# pmac_rx_secure register map
Vendor: Texas Instruments
Registers are 32-bit, read-only, reset 0x0 unless marked. A register's access mark holds for its fields unless they carry their own. Offsets are as the file gives them; [hi:lo] are bit positions; lines under a group give offsets from that group; {n}, {i} and the like mark numbered series; <NAME> marks a mode.

## pmac_rx_secure (part 2 of 3)
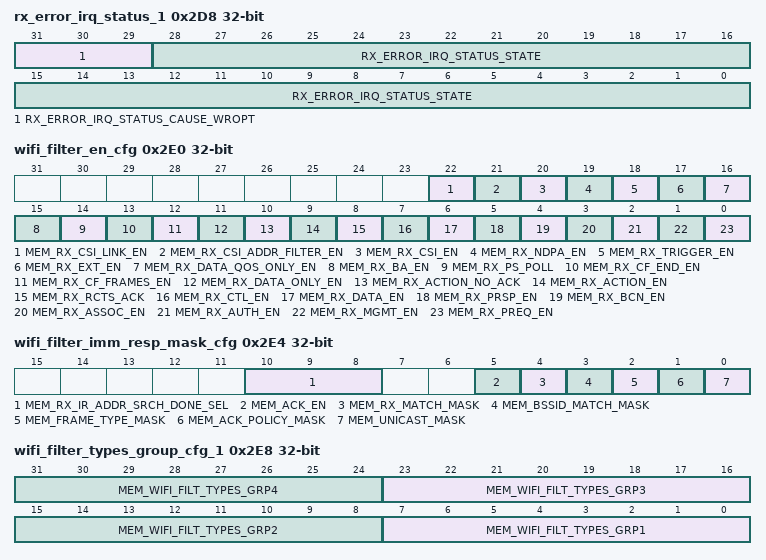
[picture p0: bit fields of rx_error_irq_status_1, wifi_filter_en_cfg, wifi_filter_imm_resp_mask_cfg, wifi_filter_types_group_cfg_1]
0x2D8 rx_error_irq_status_1 access per field
  [31:29] RX_ERROR_IRQ_STATUS_CAUSE_WROPT rw — the cause of error_irq status registers, kept in RX_ERROR_IRQ_STATUS_STATE and RX_ERROR_IRQ_STATUS_PLCP0 3'd1 = rx_bb_fifo_overflow_irq 3'd2 = rx_last2idle_timeout_irq 3'd3 = rx_bb_if_timeout_irq 3'd4 = rx_mng_state_timeout_irq 3'd5 = rx_ppdu_overflow_irq any value other than 0 will latch the CAUSE+STATE+PLCP0 status regs WROPT - clear by write 0 to enable new values write to this field will clear to 0 the values kept in RX_ERROR_IRQ_STATUS_STATE and RX_ERROR_IRQ_STATUS_PLCP0
  [28:0] RX_ERROR_IRQ_STATUS_STATE ro — state status latched in error_irq cleared when writing any value to RX_ERROR_IRQ_STATUS_CAUSE_WROPT same bit-mapping as RX_STATE_STATUS: [28] = rx_path_en; [27] = rx_scrpt_busy; [26:24] = enc_state; [23] = 1'b0; [22:20] = addr_srch_ocp_state; [19] = rx_bb_if_state; [18:16] = addr_srch_main_state; [15] = 1'b0; [14:12] = parser_state; [11: 8] = adu_mmu_ctrl_state; [ 7: 4] = adu_amsdu_parser_state; [ 3: 0] = rx_mng_state;
0x2DC rx_error_irq_status_2
  [31:0] RX_ERROR_IRQ_STATUS_PLCP0 — PHY_HEADER_WORD0 latched in error_irq cleared when writing any value to RX_ERROR_IRQ_STATUS_CAUSE_WROPT same bit-mapping as PHY_HEADER_WORD0: [31:16] - Length [15:8] - Rate [7] - Unsupported Packet [6] - SGI [5] - aggregation (at 11n) [4] - BW (at 11n) [3] - packet error [2:0] - Packet and Preamble type: 0 - 11b long preamble 1 - 11b short preamble 2 - Reserved 3 - Reserved 4 - 11a/g (legacy OFDM) 5 - Reserved 6 - 11n Mixed Mode 7 - Reserved
0x2E0 wifi_filter_en_cfg access per field reset not defined
  [22] MEM_RX_CSI_LINK_EN rw — Type: Ctl. enable choosing link CSI packets
  [21] MEM_RX_CSI_ADDR_FILTER_EN rw — Type: Ctl. enable filtering CSI through address
  [20] MEM_RX_CSI_EN rw — Type: Ctl. CSI collection enable
  [19] MEM_RX_NDPA_EN rw — Type: Ctl , Filter Group: 3 , NDP Announcement
  [18] MEM_RX_TRIGGER_EN rw — Type: Ctl , Filter Group: 8 , Trigger
  [17] MEM_RX_EXT_EN rw — Type: Ext , Filter Group: 3 , All extension types. Defined at the same group (3) as control types
  [16] MEM_RX_DATA_QOS_ONLY_EN rw — Type: Dat , Filter Group: 2 , All data types that includes only data qos (qos data, qos null data. no CF-poll no CF-Ack)
  [15] MEM_RX_BA_EN rw — Type: Ctl , Filter Group: 5 , Block ack request (BAR),Block ack
  [14] MEM_RX_PS_POLL rw — Type: Ctl , Filter Group: 4 , PS-POLL
  [13] MEM_RX_CF_END_EN rw — Type: Ctl , Filter Group: 4 , CF END, CF END ACK
  [12] MEM_RX_CF_FRAMES_EN rw — Type: Dat , Filter Group: 2 , DATA_CF_ACK, DATA_CF_POLL, DATA_CF_ACKPOLL, CF_ACK, CF_POLL, CF_ACK_POLL, QOS_DATA_CF_ACK, QOS_DATA_CF_POLL, QOS_DATA_CF_ACKPOLL, QOS_CF_POLL, QOS_CF_ACKPOLL
  [11] MEM_RX_DATA_ONLY_EN rw — Type: Dat , Filter Group: 2 , All data types that includes only data (data, null data. no qos no CF-poll no CF-Ack)
  [10] MEM_RX_ACTION_NO_ACK rw — Type: Mng , Filter Group: 1 , Action no ACK
  [9] MEM_RX_ACTION_EN rw — Type: Mng , Filter Group: 1 , Action
  [8] MEM_RX_RCTS_ACK rw — Type: Ctl , Filter Group: 4 , RTS, CTS, ACK
  [7] MEM_RX_CTL_EN rw — Type: Ctl , Filter Group: 3 , All control types
  [6] MEM_RX_DATA_EN rw — Type: Dat , Filter Group: 2 , All data types
  [5] MEM_RX_PRSP_EN rw — Type: Mng , Filter Group: 6 , Probe response
  [4] MEM_RX_BCN_EN rw — Type: Mng , Filter Group: 6 , Beacon
  [3] MEM_RX_ASSOC_EN rw — Type: Mng , Filter Group: 1 , Association request, Association response,Re-association request, Re-association response, Disassociation
  [2] MEM_RX_AUTH_EN rw — Type: Mng , Filter Group: 1 , Authentication,De-authentication
  [1] MEM_RX_MGMT_EN rw — Type: Mng , Filter Group: 1 , All management types
  [0] MEM_RX_PREQ_EN rw — Type: Mng , Filter Group: 7 , Probe request
0x2E4 wifi_filter_imm_resp_mask_cfg access per field reset not defined
  [10:8] MEM_RX_IR_ADDR_SRCH_DONE_SEL rw — rx manager config: select which signal will be used as valid signal for wifi-filter immediate_response_trigger: 0 - addr1_search_done 1 - addr2_search_done 2 - addr3_search_done 3 - header_proc_done 4 - addr4_search_done
  [5] MEM_ACK_EN rw — When set immediate response triggering feature will be enabled
  [4] MEM_RX_MATCH_MASK rw — When set rx match condition for immediate response will be ignored
  [3] MEM_BSSID_MATCH_MASK rw — When set bssid match condition for immediate response will be ignored
  [2] MEM_FRAME_TYPE_MASK rw — When set frame type condition for immediate response will be ignored
  [1] MEM_ACK_POLICY_MASK rw — When set ack policy condition for immediate response will be ignored
  [0] MEM_UNICAST_MASK rw — When set unicast condition for immediate response will be ignored
0x2E8 wifi_filter_types_group_cfg_1 rw reset not defined — if frame type match group 8 type then MEM_WIFI_FILT_TYPES_GRP8[7:0] will be loaded to cfg_filter_en[7:0] else if frame type match group 7 type then MEM_WIFI_FILT_TYPES_GRP7[7:0] will be loaded to cfg_filter_en[7:0] else if frame type match group 6 type then MEM_WIFI_FILT_TYPES_GRP6[7:0] will be loaded to cfg_filter_en[7:0] else if frame type match group 5 type then MEM_WIFI_FILT_TYPES_GRP5[7:0] will be loaded to cfg_filter_en[7:0] else if frame type match group 4 type then MEM_WIFI_FILT_TYPES_GRP4[7:0] will be loaded to cfg_filter_en[7:0] else if frame type match group 3 type then MEM_WIFI_FILT_TYPES_GRP3[7:0] will be loaded to cfg_filter_en[7:0] else if frame type match group 2 type then MEM_WIFI_FILT_TYPES_GRP2[7:0] will be loaded to cfg_filter_en[7:0] else frame type match group 1 type then MEM_WIFI_FILT_TYPES_GRP1[7:0] will be loaded to cfg_filter_en[7:0] where, Group 8 type is : Trigger Group 7 type is : Probe request Group 6 types are: Probe response or Beacon Group 5 types are: Block Ack Request (BlockAckReq)or Block Ack (BlockAck) Group 4 types are: PS-Poll or RTS or CTS or ACK or CF-End or CF-End + CF-Ack Group 3 types are: all control types or Reserved Group 2 type is : all data types Group 1 type is : all managment types cfg_filter_en[7:0] is coded as follow: cfg_filter_en [0] - unicast_filter_en cfg_filter_en [1] - multicast_filter_en cfg_filter_en [2] - broadcast_filter_en cfg_filter_en [3] - sa_filter_en cfg_filter_en [4] - bssid_filter_en cfg_filter_en [5] - ssid_filter_en cfg_filter_en [6] - fcs_filter_en cfg_filter_en [7] - bssid_partial_filter_en (For Multiple BSSID)
  [8n-1:8n-8] MEM_WIFI_FILT_TYPES_GRP{n} (n=1..4) — Defines which type of filters should be enforced on received frame of type group {n}
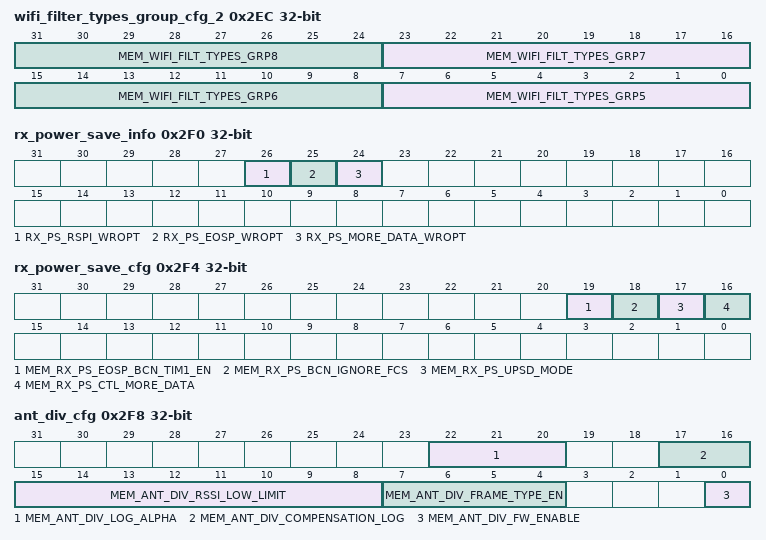
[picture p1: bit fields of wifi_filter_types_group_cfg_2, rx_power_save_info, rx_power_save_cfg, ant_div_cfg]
0x2EC wifi_filter_types_group_cfg_2 rw reset not defined — if frame type match group 8 type then MEM_WIFI_FILT_TYPES_GRP8[7:0] will be loaded to cfg_filter_en[7:0] else if frame type match group 7 type then MEM_WIFI_FILT_TYPES_GRP7[7:0] will be loaded to cfg_filter_en[7:0] else if frame type match group 6 type then MEM_WIFI_FILT_TYPES_GRP6[7:0] will be loaded to cfg_filter_en[7:0] else if frame type match group 5 type then MEM_WIFI_FILT_TYPES_GRP5[7:0] will be loaded to cfg_filter_en[7:0] else if frame type match group 4 type then MEM_WIFI_FILT_TYPES_GRP4[7:0] will be loaded to cfg_filter_en[7:0] else if frame type match group 3 type then MEM_WIFI_FILT_TYPES_GRP3[7:0] will be loaded to cfg_filter_en[7:0] else if frame type match group 2 type then MEM_WIFI_FILT_TYPES_GRP2[7:0] will be loaded to cfg_filter_en[7:0] else frame type match group 1 type then MEM_WIFI_FILT_TYPES_GRP1[7:0] will be loaded to cfg_filter_en[7:0] where, Group 8 type is : Trigger Group 7 type is : Probe request Group 6 types are: Probe response or Beacon Group 5 types are: Block Ack Request (BlockAckReq)or Block Ack (BlockAck) Group 4 types are: PS-Poll or RTS or CTS or ACK or CF-End or CF-End + CF-Ack Group 3 types are: all control types or Reserved Group 2 type is : all data types Group 1 type is : all managment types cfg_filter_en[7:0] is coded as follow: cfg_filter_en [0] - unicast_filter_en cfg_filter_en [1] - multicast_filter_en cfg_filter_en [2] - broadcast_filter_en cfg_filter_en [3] - sa_filter_en cfg_filter_en [4] - bssid_filter_en cfg_filter_en [5] - ssid_filter_en cfg_filter_en [6] - fcs_filter_en cfg_filter_en [7] - bssid_partial_filter_en (For Multiple BSSID)
  [8n-33:8n-40] MEM_WIFI_FILT_TYPES_GRP{n} (n=5..8) — Defines which type of filters should be enforced on received frame of type group {n}
0x2F0 rx_power_save_info access per field — Part of DB Access describing POWER SAVE INFO
  [26] RX_PS_RSPI_WROPT rw — for mesh usage (11s only) . receiver service period indication.
  [25] RX_PS_EOSP_WROPT rw — Reflects the most updated EOSP received by the PMAC. The source of this bit is the QOS control field of the header. It is indicating that AP finished its TX in the current service period.
  [24] RX_PS_MORE_DATA_WROPT rw — Reflects the most updated more data received by the PMAC. This bit source is from the frame control field. It is indicating that the AP got more frames to transmit, and that the STA is required to send another trigger frame.
0x2F4 rx_power_save_cfg access per field — Part of DB Access describing POWER SAVE INFO
  [19] MEM_RX_PS_EOSP_BCN_TIM1_EN rw — Enabled updating esop data on beacon with tim set to 1
  [18] MEM_RX_PS_BCN_IGNORE_FCS rw — This bit enables the 'psd_ps_changed' indication, to IGNORE fcs check when the received frame is beacon. (if this bit set to '1' - this beacon is relevant for PSD indication update, even if there is fcs error on the received beacon).
  [17] MEM_RX_PS_UPSD_MODE rw — Unschedule APSD mode.
  [16] MEM_RX_PS_CTL_MORE_DATA rw — This bit sets the MORE_DATA bit in Data base when the recived frame is control frame (ack, BA, multi TID BA and multi STA BA if directed to specific station).
0x2F8 ant_div_cfg access per field reset not defined — PMAC-RX: Antenna Diversity Module Configuration registers
  [22:20] MEM_ANT_DIV_LOG_ALPHA rw — for Alpha-filter: between 0-7 (higher value corresponds to slower filter reaction)
  [17:16] MEM_ANT_DIV_COMPENSATION_LOG rw — 0 Log 3 1 Log 4 2 Log 5
  [15:8] MEM_ANT_DIV_RSSI_LOW_LIMIT rw — Low threshold for curiosity to start (Default: -70dBm [0x28])
  [7:4] MEM_ANT_DIV_FRAME_TYPE_EN rw — Defines which types should be received (other types will be dropped). (default=7) 0 - beacon 1 - data 2 - immediate response 3 - other
  [0] MEM_ANT_DIV_FW_ENABLE rw — FW enable/disable
0x2FC avg_rssi_status reset not defined — Information of the Average RSSI from the Antenna Diversity module
  [7:0] AVG_RSSI_THR_INTERRUPT_BITMAP_RDCL — Interrupt status bitmap according to 'avg_rssi_thr_id' input from Role-DB
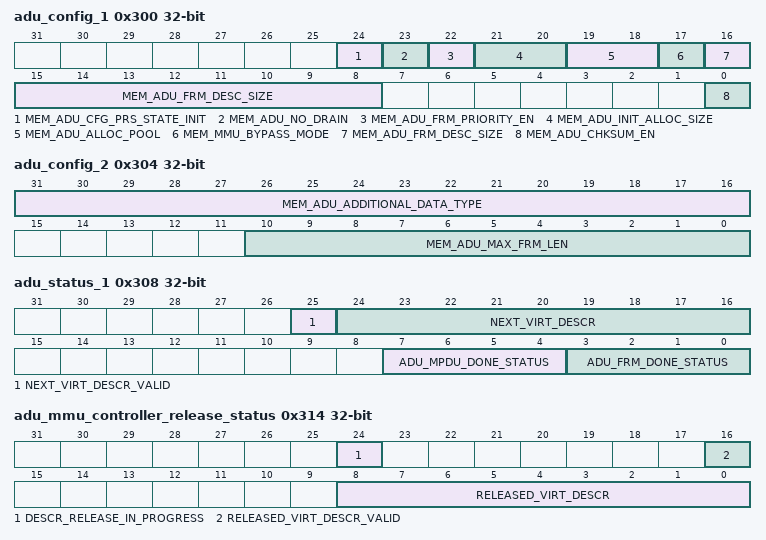
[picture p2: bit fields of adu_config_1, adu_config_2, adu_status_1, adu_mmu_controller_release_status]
0x300 adu_config_1 access per field reset not defined — 1 - No Drain in case of an allocated MSDU has length > remainder bytes at AES. Remainder bytes are copied to allocated block at PRAM. 0 - Drain in case of an allocated MSDU has length > remainder bytes at AES. Remainder bytes are thrown away.
  [24] MEM_ADU_CFG_PRS_STATE_INIT rw — Configure whether 'prs_state' initial state is: 'PARS_IDLE' or 'MPDU_DONE': If '1': 'prs_state' moves straight at the 1st clock after reset, from 'PRS_IDLE' state to 'MPDU_DONE' state (which is the steady state of the state-machine, after receiving 1st packet) If '0' (defualt) : 'prs_state' stays at 'PRS_IDLE' state (until 1st packet recieved, never goes back to this state again) (This bit was added to deal with PMAC_RX gets stuck, when receiving 1st packet after reset of length 1) CAUTION: This bit must be set before enabling "PMAC_ACM__ENABLE__MEM_RX_PATH_EN", otherwise PMAC might already process new packets
  [23] MEM_ADU_NO_DRAIN rw
  [22] MEM_ADU_FRM_PRIORITY_EN rw — Enable prioritizing frame according to priority set by rx manager
  [21:20] MEM_ADU_INIT_ALLOC_SIZE rw — initial allocation. 0. 256 1. 256+128 2. 512 3. Full descriptor (depending on the 2k/4k input from the MMU)
  [19:18] MEM_ADU_ALLOC_POOL rw — Allocation Pool: TX (2'b00) / RX (2'b01) - Default / Tx management (2'b10)/ TCP ACK (S/W)(2'b11)
  [17] MEM_MMU_BYPASS_MODE rw — Set by S/W when MMU is not functional. ADU retrieve Desc ID from by popping de-allocation FIFO.
  [16:8] MEM_ADU_FRM_DESC_SIZE rw — Frame descriptor size up to 512 bytes
  [0] MEM_ADU_CHKSUM_EN rw — Enable ADU CheckSum calc (partly calc)
0x304 adu_config_2 access per field reset not defined
  [31:16] MEM_ADU_ADDITIONAL_DATA_TYPE rw — Additional data type to be compared to Ethernet Type. For supporting future data types other then 0x0800 for IPV4 and 0x86DD for IPV6
  [10:0] MEM_ADU_MAX_FRM_LEN rw — Frame max payload length in words (not bytes) from MMU prespective. Frames that have "payload length" > MAX_FRM_LEN will be chopped accordingly. Payload length is: in MSDU - Payload length field (2B - a.k.a parsed len), not including padding field. in MPDU - Total len reported by Rx manager [-MIC] - mpdu header len reported by rx manager [-sec hdr] In general , MAX_FRM_LEN should be loaded with Max operation size for Payload section in the MMU: Payload section For MPDU is: mblk_size-desc_size-mpdu_hdr [-2B_hdr_hole] [-sec hdr] Payload section For 1st MSDU is: mblk_size-desc_size-mpdu_hdr [-2B_hdr_hole] [-sec hdr] -sub frm hdr Payload section For not 1st MSDU is: mblk_size-desc_size-sub frm hdr Example: for mblk 2K, not protected, where desc size set to 96B and mpdu-hdr 10B: MAX_FRM_LEN = 2K-desc_size-mpdu_hdr = 2048B-96B-10B =1942B = 485.5W --floor -- > = 485W (0x1E5) Note that MAX_FRM_LEN can be used for "sniffer mode" (i.e set low value) Note that Total len reported by Rx manager is chooped anyway to 8KB (2KW). Note that, by Spec, MSDU payload len field is limited up to 2304B.
0x308 adu_status_1
  [25] NEXT_VIRT_DESCR_VALID — MMU response notifying valid virtual descriptor is alllocated
  [24:16] NEXT_VIRT_DESCR — MMU response with virtual desc as frame base address
  [7:4] ADU_MPDU_DONE_STATUS — MPDU Done related "Bad" status's that indicate something went wrong during copying this MPDU from AES to PRAM: [0] md_range_err_during_frm At least one MMU range error occurred during processing this mpdu (MMU is out of range). Set condition: serror Reset condition: mpdu start [1] md_init_alloc_failure Initial alloc fail. Set condition: Get address 1 (request for initial mem resource) failed Reset condition: mpdu start [2] md_msdu_alloc_failure At least one MSDU failed to acquire allocation. (Note that realloc failure is an unknown event from ADU perspective. Instead, ADU reports serror at the end of frame and end of mpdu). Set condition: Get address 2 (request for msdu mem resource) failed Reset condition: mpdu start [3] md_remainder_lt_min Remainder < 14 right after frame done (or msdu drain) Set condition: Remainder < 14 Reset condition: mpdu start
  [3:0] ADU_FRM_DONE_STATUS — Frame Done related "Bad" status's that indicate something went wrong during copying this frame from AES to PRAM: [0] fd_range_err_during_frm MMU accessed unallocated range during processing this frame Set condition: range_err drom MMU Reset condition: mpdu start | frm_done_ack [1] fd_parsed_gt_remainder Wrong msdu len. Parsed len > total length remainder (after headers and previous msdu's subtraction). Set condition: parsed_len > remainder Reset condition: mpdu start [2] fd_payload_gt_max Wrong msdu or mpdu payload length. Parsed len or mpdu payload len > cfg reg (max value). The cfg reg holds max operation capability in terms of mem resource: 2K/4K - desc - wlan header -sec header - sub frame header (in case AMSDU). Set condition: parsed_len > max (mem_max_sub_frm_len) Reset condition: mpdu start [3] fd_abort_during_frm ADU got abort during processing this frame. Set condition: Phy abort & ADU busy Reset condition: mpdu start
0x310 adu_mmu_controller_release_request access per field
  [0] MEM_DESCR_RELEASE_REQ_WRCL wo — S/W request to release virtual descriptor if held by adu mmu controller
0x314 adu_mmu_controller_release_status
  [24] DESCR_RELEASE_IN_PROGRESS — 1- s/w request to release virtual descriptor is in progress. 0- s/w request to release virtual descriptor is is done. in case an allocated descr exists at the time of the request, RELEASED_VIRT_DESCR_VALID will be 1 and descr ID will reside in RELEASED_VIRT_DESCR.
  [16] RELEASED_VIRT_DESCR_VALID — Released virtual descriptor ID valid bit (per S/W request). 1 - virt-desc exists, s/w can dealloc 0 - virt-desc doesn't exist
  [8:0] RELEASED_VIRT_DESCR — Released virtual descriptor ID (per S/W request)
0x31C rx_link_connected_role_id access per field reset 0xF
  [3:0] MEM_LINK_CONNECTED_ROLE_ID_WROPT rw — the role ID attached to this link
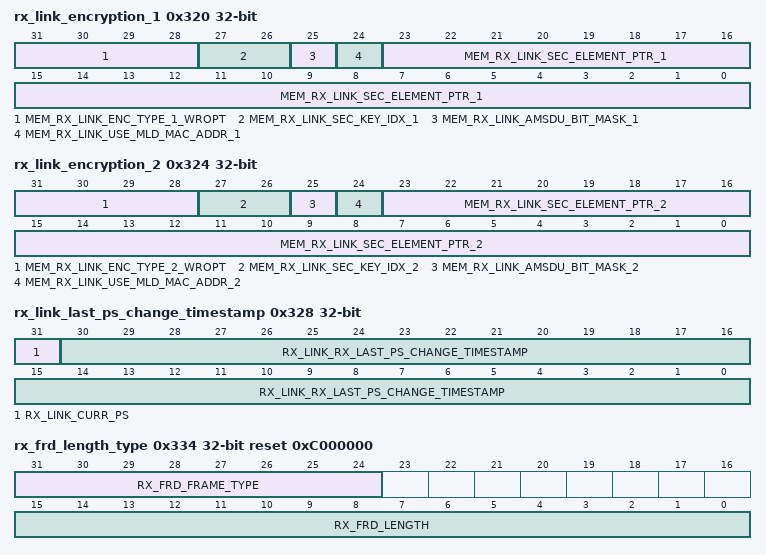
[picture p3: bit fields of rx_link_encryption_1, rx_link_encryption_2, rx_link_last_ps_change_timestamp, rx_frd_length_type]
0x320 rx_link_encryption_1 rw
  [31:28] MEM_RX_LINK_ENC_TYPE_1_WROPT — Type of encryption. used by PMAC to identify need for AES encryption on the fly. coding: 4'd0 : none 4'd1 : WEP 4'd2 : TKIP 4'd3 : AES 4'd4 : GEM 4'd5 - 4'd15 : reserved (treated as none) (wropt - will be cleared by HW at new MPDU start) enumeration defined in: /vobs/cc33xx/modules/wsoc_wmac/hdl/rtl/wsoc_wmac_defines.v
  [27:26] MEM_RX_LINK_SEC_KEY_IDX_1 — key index
  [25] MEM_RX_LINK_AMSDU_BIT_MASK_1 — key index
  [24] MEM_RX_LINK_USE_MLD_MAC_ADDR_1 — Selector for key addresses
  [23:0] MEM_RX_LINK_SEC_ELEMENT_PTR_1 — Pointer to the structure holding the encryption information.
0x324 rx_link_encryption_2 rw
  [31:28] MEM_RX_LINK_ENC_TYPE_2_WROPT — Type of encryption. used by PMAC to identify need for AES encryption on the fly. coding: 4'd0 : none 4'd1 : WEP 4'd2 : TKIP 4'd3 : AES 4'd4 : GEM 4'd5 - 4'd15 : reserved (treated as none) (wropt - will be cleared by HW at new MPDU start) enumeration defined in: /vobs/cc33xx/modules/wsoc_wmac/hdl/rtl/wsoc_wmac_defines.v
  [27:26] MEM_RX_LINK_SEC_KEY_IDX_2 — key index
  [25] MEM_RX_LINK_AMSDU_BIT_MASK_2 — key index
  [24] MEM_RX_LINK_USE_MLD_MAC_ADDR_2 — Selector for key addresses
  [23:0] MEM_RX_LINK_SEC_ELEMENT_PTR_2 — Pointer to the structure holding the encryption information.
0x328 rx_link_last_ps_change_timestamp
  [31] RX_LINK_CURR_PS — current PS (after the chage indication)
  [30:0] RX_LINK_RX_LAST_PS_CHANGE_TIMESTAMP — timestamp of the ast rx frame which signaled that the link has change PS mode.
0x32C rx_frd_scripter_information rw
  [31:0] MEM_RX_FRD_SCRIPTER_INFORMATION — general-purpose information written by scripter
0x330 rx_frd_address reset 0x45400060
  [31:0] RX_FRD_ADDRESS — Address of the frame first byte of Payload in RAM full 32-bit that can be used by cortex, include 8-MSB [31:24] (Default == MCU_TO_PRAM_UPPER_ADDR==0x45) 24-LSB [23:0] are normal SOC address. where: Default[23:21] == mem_pram_base_addr[2:0]==0x2) Default[23:21] == mem_adu_frm_desc_size[8:0]==0x60)
0x334 rx_frd_length_type reset 0xC000000
  [31:24] RX_FRD_FRAME_TYPE — MAC header Frame Control filed bits [7:0] [1:0] - protocol version [3:2] - type (Default 0x3 == frm_type is ext (not: data,ctrl,mgmt)) [7:4] - subtype
  [15:0] RX_FRD_LENGTH — payload length as reported from ADU at frame_start
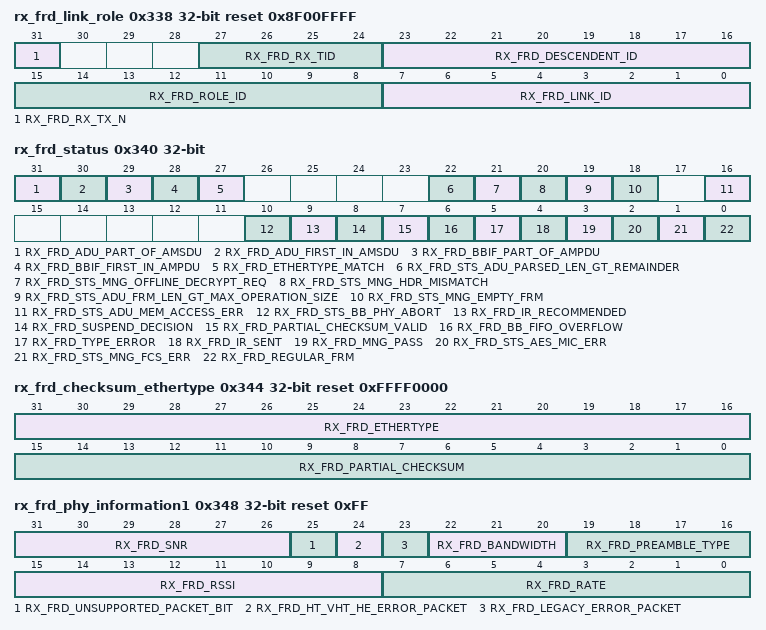
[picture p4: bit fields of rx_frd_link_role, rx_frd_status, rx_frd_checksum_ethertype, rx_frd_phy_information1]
0x338 rx_frd_link_role reset 0x8F00FFFF
  [31] RX_FRD_RX_TX_N — indicates if current descriptor is in tx flow drection of rx flow direction 1: rx 0: tx
  [27:24] RX_FRD_RX_TID — frame's RX_TID
  [23:16] RX_FRD_DESCENDENT_ID — Descendent ID. Identify the descendent in mesh topology.
  [15:8] RX_FRD_ROLE_ID — Role index. Identified by the reciever address of the frame. 0xFF means - role unknown.
  [7:0] RX_FRD_LINK_ID — Link index, identified by the transmitter address of the frame. value 0xFF means link was not identified.
0x33C rx_frd_pmac_first_byte_timestamp
  [31:0] RX_FIRST_BYTE_TIMESTAMP — Timestamp written by PMAC. Indicating when frame was recieved.
0x340 rx_frd_status — HW decisions and indications on the frame including outputs from wifi filter (WF), ADU, manager (MNG) and address search (ADRS) or baseband (BB)
  [31] RX_FRD_ADU_PART_OF_AMSDU — Frame was recieved as part of AMSDU
  [30] RX_FRD_ADU_FIRST_IN_AMSDU — Frame was the first in AMSDU
  [29] RX_FRD_BBIF_PART_OF_AMPDU — MPDU was recived as part of AMPDU
  [28] RX_FRD_BBIF_FIRST_IN_AMPDU — MPDU was the first in AMPDU
  [27] RX_FRD_ETHERTYPE_MATCH — Output at Frm Done - Extracted Eth type is matched to one of data types (0x0800 for IPV4 & 0x86DD for IPV6 or cfg'd value mem_adu_additional_data_type)
  [22] RX_FRD_STS_ADU_PARSED_LEN_GT_REMAINDER — AMSDU sub frame length is greater than MPDU ramining byte counter
  [21] RX_FRD_STS_MNG_OFFLINE_DECRYPT_REQ — rx manager status protected bit is set but it is not AES that we can decrypt (WEP, TKIP, not to us , key ID mismatch etc)
  [20] RX_FRD_STS_MNG_HDR_MISMATCH — rx manager status - header length (set by frm_ctrl) is longer than mpdu total length
  [19] RX_FRD_STS_ADU_FRM_LEN_GT_MAX_OPERATION_SIZE — ADU comaprison to a max configured size failed. this size contain a max value of max wlan header size + security overhead + MSDU header + descriptor size
  [18] RX_FRD_STS_MNG_EMPTY_FRM — descriptor was created on an empty PPDU (NDP, unsupported etc)
  [16] RX_FRD_STS_ADU_MEM_ACCESS_ERR — allocated descriptor with re-alloc failure
  [10] RX_FRD_STS_BB_PHY_ABORT — BB indication - frame was aborted by the phy rx_last signal
  [9] RX_FRD_IR_RECOMMENDED — Immediate response recommendation by WF or SCB (this is not promising that the eventually IR is triggered) <--> (ir_trig_wf_decision or ir_trig_scb_decision)
  [8] RX_FRD_SUSPEND_DECISION — Decision on suspending the received frame. It can be for either of the following: 1. Suspend recommendation without stomp 2. Suspend recommendation with stomp 3. Suspend recommendation for Spatial-Reuse 4. Suspend from BET module on recevied Decision on suspending the received frame. It can be for either of the following: 1. Suspend recommendation without stomp 2. Suspend recommendation with stomp 3. Suspend recommendation for Spatial-Reuse 4. Suspend from BET module on received Beacon
  [7] RX_FRD_PARTIAL_CHECKSUM_VALID — ADU Output at Frm Done - Checksum calculation valid signal of RX_FRD_PARTIAL_CHECKSUM
  [6] RX_FRD_BB_FIFO_OVERFLOW — BB_FIFO overflow - write from PHY while fifo is full
  [5] RX_FRD_TYPE_ERROR — rx_manager + scripter are in SCR_TYPE_ERROR also known as HEADER_PROCESSING_AVOID activated in the following cases: 1. type/sybtype is reserved 2. protocol is not "00"
  [4] RX_FRD_IR_SENT — [Warning: UNRELIABLE information for both MPDUs and AMPDUs] rx requested to transmit a response for this frame
  [3] RX_FRD_MNG_PASS — HW frame_deliver to SW
  [2] RX_FRD_STS_AES_MIC_ERR — Frame MIC check failed (AES)
  [1] RX_FRD_STS_MNG_FCS_ERR — frame FCS status
  [0] RX_FRD_REGULAR_FRM — indicate that this frame is a candidate for SW fast path processing
0x344 rx_frd_checksum_ethertype reset 0xFFFF0000
  [31:16] RX_FRD_ETHERTYPE — Ethertype field. Extracted by PMAC HW in case frame is not encrypted or AES decrypted by the PMAC. in other case this field should be set by SW.
  [15:0] RX_FRD_PARTIAL_CHECKSUM — Partial checksum, calculated from pre-defined offset from the wlan header. used as preliminary value for TCP checksum calculation.
0x348 rx_frd_phy_information1 reset 0xFF
  [31:26] RX_FRD_SNR, [25] RX_FRD_UNSUPPORTED_PACKET_BIT, [24] RX_FRD_HT_VHT_HE_ERROR_PACKET, [23] RX_FRD_LEGACY_ERROR_PACKET, [22:20] RX_FRD_BANDWIDTH, [19:16] RX_FRD_PREAMBLE_TYPE, [15:8] RX_FRD_RSSI, [7:0] RX_FRD_RATE
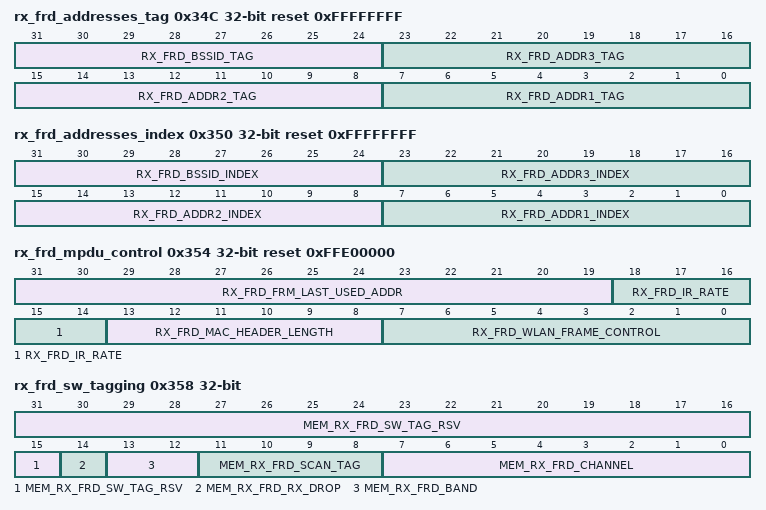
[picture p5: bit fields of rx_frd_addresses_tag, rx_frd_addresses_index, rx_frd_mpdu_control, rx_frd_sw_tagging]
0x34C rx_frd_addresses_tag reset 0xFFFFFFFF — Results collected from address search mechanism by the the header processing in the PMAC TAG enumeration: 8'd 7 = DESCEND_TAG 8'd 6 = PEER_TAG 8'd 5 = MULTICAST_TAG 8'd 4 = LOCAL_TAG 8'd 3 = RESERVED_3_TAG 8'd 2 = RESERVED_2_TAG 8'd 1 = LOCAL_MESH_TAG 8'd 0 = PARENT_MESH_TAG 8'h FF = ERROR_TAG
  [31:24] RX_FRD_BSSID_TAG, [23:16] RX_FRD_ADDR3_TAG, [15:8] RX_FRD_ADDR2_TAG, [7:0] RX_FRD_ADDR1_TAG
0x350 rx_frd_addresses_index reset 0xFFFFFFFF — Results collected from address search mechanism by the the header processing in the PMAC index field value is according to TAG field: TAG = 7 : index = 0..127 descendants TAG = 6 : index = 0..63 links TAG = 5 : index = 0..31 multicast TAG = 4 : index = 0..15 local addr TAG = 3 : index = 0..7 (reserved) TAG = 2 : index = 0..3 (reserved) else : index = 0xFF
  [31:24] RX_FRD_BSSID_INDEX, [23:16] RX_FRD_ADDR3_INDEX, [15:8] RX_FRD_ADDR2_INDEX, [7:0] RX_FRD_ADDR1_INDEX
0x354 rx_frd_mpdu_control reset 0xFFE00000
  [31:19] RX_FRD_FRM_LAST_USED_ADDR — Last used address is the last address used by ADU toward PRAM. 1. in case no word is copied: Last used address points to the last descriptor word. 2. in case of zero length frame: Last used address is don't care - preserving last used address from previous non- zero length frame. 3. in case of ocp block scenario (Abort, rx manager block, mmu range err, sniffer-size/max-frame-length reached) that occurred prior to "get address": Last used address will be don't care - preserving last used address from previous frame.
  [18:14] RX_FRD_IR_RATE — [Warning: UNRELIABLE information for both MPDUs and AMPDUs] rate that the response shopuld be transmitted in by the tx
  [13:8] RX_FRD_MAC_HEADER_LENGTH — Length in bytes of MAC Layers Header (including MPDU Header, AES Security Header and AMSDU sub headers
  [7:0] RX_FRD_WLAN_FRAME_CONTROL — MAC header Frame Control filed bits [15:8] [0] = Frame Control [8] = to DS [1] = Frame Control [9] = from DS [2] = Frame Control [10] = more frag [3] = Frame Control [11] = retry [4] = Frame Control [12] = power management [5] = Frame Control [13] = more data [6] = Frame Control [14] = protected frame [7] = Frame Control [15] = order (ht_present, ht_ctrl_exist)
0x358 rx_frd_sw_tagging rw — Word copied from dedicated register into the descriptor. Register content is set by the SW, ofr tagging in real time.
  [31:15] MEM_RX_FRD_SW_TAG_RSV
  [14] MEM_RX_FRD_RX_DROP — If set - Rx SW thread should drop the frame and not deliver to netex or supplicant
  [13:12] MEM_RX_FRD_BAND
  [11:8] MEM_RX_FRD_SCAN_TAG
  [7:0] MEM_RX_FRD_CHANNEL
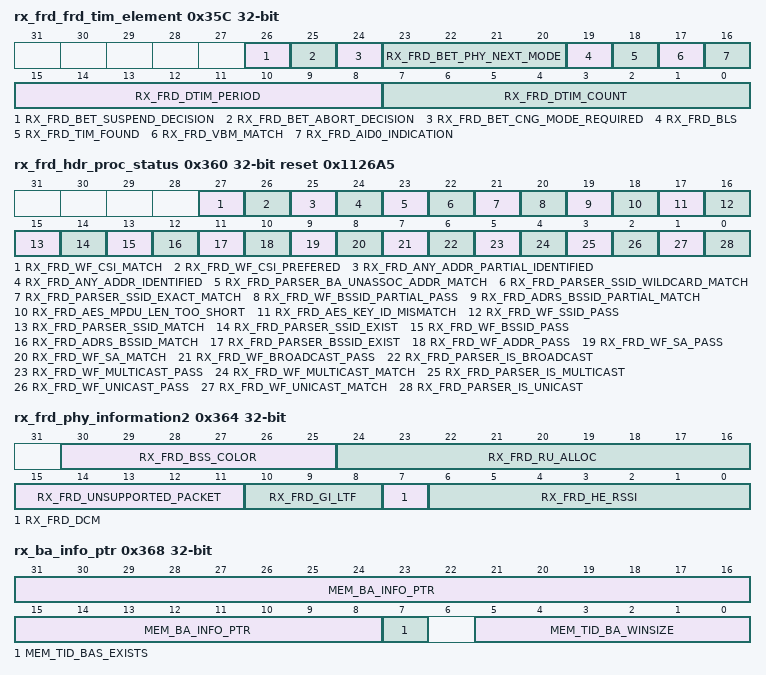
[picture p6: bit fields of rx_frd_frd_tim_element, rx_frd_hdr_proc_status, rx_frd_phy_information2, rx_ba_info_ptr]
0x35C rx_frd_frd_tim_element
  [26] RX_FRD_BET_SUSPEND_DECISION — Decision by the BET module to suspend the received beacon.
  [25] RX_FRD_BET_ABORT_DECISION — Decision by the BET module to abort the received beacon (it does not mean the request is sent to PHY, since it depends also if Change mode required). Note: since HW abort without change mode is NOT allowed, {abort_decision == 1 & change_mode_required == 0} means that no abort_request was driven towards phy. It just means that abort conditions were met (BET internal logic only)
  [24] RX_FRD_BET_CNG_MODE_REQUIRED — Decision by the BET module (according to beacon info) to send a request to the PHY that change mode is required
  [23:20] RX_FRD_BET_PHY_NEXT_MODE — Recommendation of the BET module toward the PHY, on the Next phy mode (
  [19] RX_FRD_BLS — Indication for BLS rx-frame (Beacon late synchronization)
  [18] RX_FRD_TIM_FOUND — Indication of Beacon received with TIM Element
  [17] RX_FRD_VBM_MATCH — This bit is set to 1 in TIM elements with a value of 0 in the DTIM Count field when one or more group addressed MSDUs/MMPDUs are buffered at the AP.
  [16] RX_FRD_AID0_INDICATION — 1 - Broadcast / multicast traffic is buffered, and going to be transmitter after the beacon. 0 - no Broadcast / multicast traffic after this beacon.
  [15:8] RX_FRD_DTIM_PERIOD — indicates the number of beacon intervals between successive DTIMs. If all TIMs are DTIMs, the DTIM Period field has the value 1. The DTIM Period value 0 is reserved.
  [7:0] RX_FRD_DTIM_COUNT — Indicates how many Beacon frames (including the current frame) appear before the next DTIM. A DTIM Count of 0 indicates that the current TIM is a DTIM.
0x360 rx_frd_hdr_proc_status reset 0x1126A5 — HW decisions and indications on the frame including outputs from wifi filter (WF), ADU, manager (MNG) and address search (ADRS) or baseband (BB)
  [27] RX_FRD_WF_CSI_MATCH — For frame where addr2 matchs CSI address
  [26] RX_FRD_WF_CSI_PREFERED — For frame which CSI info is prefered to be saved
  [25] RX_FRD_ANY_ADDR_PARTIAL_IDENTIFIED — Any of the MAC addresses of the frame is partially identified: any_addr_partial_identified = (addr1_partial_match or addr2_partial_match or addr3_partial_match)
  [24] RX_FRD_ANY_ADDR_IDENTIFIED — Any of the MAC addresses of the frame is identified: any_addr_identified = (addr1_match or addr2_match or addr3_match or addr4_match);
  [23] RX_FRD_PARSER_BA_UNASSOC_ADDR_MATCH
  [22] RX_FRD_PARSER_SSID_WILDCARD_MATCH — parser comparison
  [21] RX_FRD_PARSER_SSID_EXACT_MATCH — parser comparison
  [20] RX_FRD_WF_BSSID_PARTIAL_PASS — bssid filter passed
  [19] RX_FRD_ADRS_BSSID_PARTIAL_MATCH — address search bssid partial match
  [18] RX_FRD_AES_MPDU_LEN_TOO_SHORT — AES protected frame but frame length doesnt match AES reuired length (header + sec header + MIC + 1B payload + FCS)
  [17] RX_FRD_AES_KEY_ID_MISMATCH — key id received from the frame doesnt match the detected Link possible key IDs
  [16] RX_FRD_WF_SSID_PASS — SSID filter passed
  [15] RX_FRD_PARSER_SSID_MATCH — parser comparison
  [14] RX_FRD_PARSER_SSID_EXIST — parser indication - SSID exists in this frame
  [13] RX_FRD_WF_BSSID_PASS — bssid filter passed
  [12] RX_FRD_ADRS_BSSID_MATCH — address search bssid match
  [11] RX_FRD_PARSER_BSSID_EXIST — bssid address is present in the header
  [10] RX_FRD_WF_ADDR_PASS — all addres sfilter pased (uni, multi, sa, broadcast)
  [9] RX_FRD_WF_SA_PASS — sa filter passed
  [8] RX_FRD_WF_SA_MATCH — addr3 is match and is local
  [7] RX_FRD_WF_BROADCAST_PASS — BC filter passed
  [6] RX_FRD_PARSER_IS_BROADCAST — addr1 is BC
  [5] RX_FRD_WF_MULTICAST_PASS — MC filter passed
  [4] RX_FRD_WF_MULTICAST_MATCH — addr 1 is multicast and ADRS tag is known MC
  [3] RX_FRD_PARSER_IS_MULTICAST — Addr1 MC indication (bit 40 in address )
  [2] RX_FRD_WF_UNICAST_PASS — unicast filter pass
  [1] RX_FRD_WF_UNICAST_MATCH — unicast frame + ADRS indication that the address is local
  [0] RX_FRD_PARSER_IS_UNICAST — parser indication. frame has a unicast address.
0x364 rx_frd_phy_information2
  [30:25] RX_FRD_BSS_COLOR, [24:16] RX_FRD_RU_ALLOC, [15:11] RX_FRD_UNSUPPORTED_PACKET, [10:8] RX_FRD_GI_LTF, [7] RX_FRD_DCM, [6:0] RX_FRD_HE_RSSI
0x368 rx_ba_info_ptr access per field
  [31:8] MEM_BA_INFO_PTR rw — the field holds the pointer to the BA bitmap in cases where we use full BA (and not partial) this field is connected to the rx scripter's base5
  [7] MEM_TID_BAS_EXISTS rw — indication that BA session exists
  [5:0] MEM_TID_BA_WINSIZE rw — Ba session window size
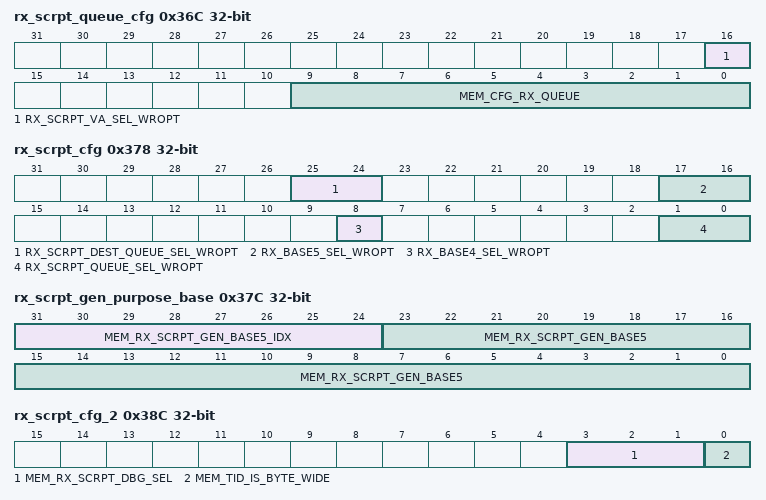
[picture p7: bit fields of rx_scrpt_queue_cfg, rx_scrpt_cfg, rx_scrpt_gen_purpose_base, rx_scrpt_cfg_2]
0x36C rx_scrpt_queue_cfg access per field reset not defined
  [16] RX_SCRPT_VA_SEL_WROPT rw
  [9:0] MEM_CFG_RX_QUEUE rw — fifo queue used when the selector is at the configurable fifo option
0x370 rx_scrpt_link_addr access per field reset not defined
  [23:0] RX_SCRPT_LINK_ADDR_WROPT rw — full link address
0x374 rx_scrpt_role_addr access per field reset not defined
  [23:0] RX_SCRPT_ROLE_ADDR_WROPT rw — full role address
0x378 rx_scrpt_cfg access per field reset not defined
  [25:24] RX_SCRPT_DEST_QUEUE_SEL_WROPT rw — select which fifo base is used for register RX_SCRPT_DEST_Q clears to 0 on every scrpt_start_stb set by the manager. scripter/ocp can write it. 00: sw rx complete (const) 01: de-alloc fifo(const) 10: mem_cfg_rx_queue (config general purpose register)
  [17:16] RX_BASE5_SEL_WROPT rw — 2'b00 scripter's base 5 points to MMU cyclic debug buffer base. 2'b01 scripter's base 5 points to {gen_base4[23:2, 2'b0} + gen_purpose_idx4 * 2 2'b10 scripter's base 5 points to mem_ba_info_ptr the field clears to 0 on script start
  [8] RX_BASE4_SEL_WROPT rw — 1'b0 scripter's base 4 points to mem_rfd_addr. 1'b1 scripter's base 4 points to mem_rfd_addr + security header additional offset (sum of: +2 for QC, +6 for A4, +4 for HTC header) the field clears to 0 on script start
  [1:0] RX_SCRPT_QUEUE_SEL_WROPT rw — select which fifo base is used for scripter base 0 clears to 0 on every scrpt_start_stb set by the manager. scripter/ocp can write it. 00: sw rx complete (const) 01: de-alloc fifo(const) 10: tmp_amsdu queue (const) 11: mem_cfg_rx_queue (config general purpose register)
0x37C rx_scrpt_gen_purpose_base rw
  [31:24] MEM_RX_SCRPT_GEN_BASE5_IDX, [23:0] MEM_RX_SCRPT_GEN_BASE5
0x380 rx_scrpt_decision access per field
  [0] RX_SCRPT_REJECT_STB_WRCL wo — write of '1' to this bit will generate rx_reject_stb needed as a replacement of JOIN to dealloc, in cases where there is no memory allocation and no JOIN command
0x384 rx_scrpt_va_idx
  [8:0] RX_SCRPT_VA_IDX — current proccessed virtual address allocated by the ADU (MPDU or MSDU descriptor)
0x388 rx_scrpt_dest_q
  [15:6] RX_SCRPT_DEST_Q — destination queue for join commands. controlled by the manager.(de-alloc, rx_complete or configured queue)
0x38C rx_scrpt_cfg_2 access per field reset not defined
  [3:1] MEM_RX_SCRPT_DBG_SEL rw
  [0] MEM_TID_IS_BYTE_WIDE rw — 1'b1 - TID field in the link DB is one byte - window side and BA session exsits. 1'b0 - TID fields is 32 bit wide and also contains the BA session context pointer (pointer to bitmap and SSN) this influences base 6 - if set, TID struct is accessed as link + tid index and if cleared as link + tid<<2
0x390 rx_scrpt_va_offset access per field reset not defined
  [12:0] RX_SCRPT_CURR_VA_OFFSET_WROPT rw — offset inside the descriptor. reset to 0 on every script_start_stb. can be directly written in order to provide larger offsets than what the scripter command offset can allow.
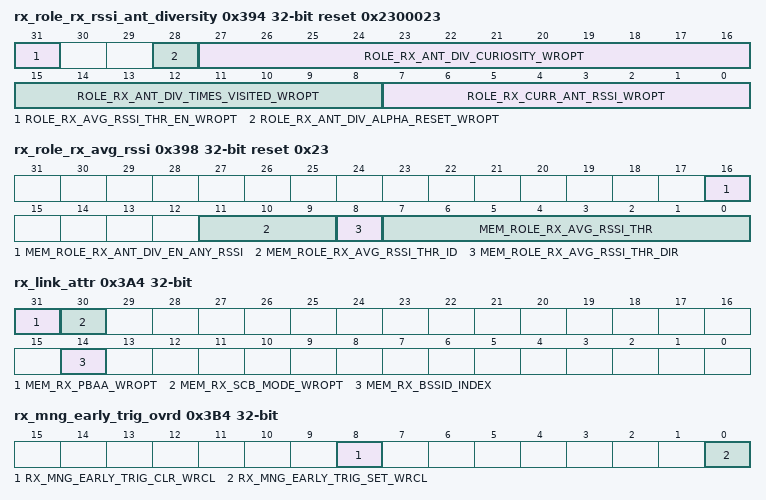
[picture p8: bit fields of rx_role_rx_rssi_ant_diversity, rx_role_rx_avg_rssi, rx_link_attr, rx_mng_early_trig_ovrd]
0x394 rx_role_rx_rssi_ant_diversity access per field reset 0x2300023 — ROLE-DB with Antenna Diversity data (Current RSSI, Curiosity, Times Visited)
  [31] ROLE_RX_AVG_RSSI_THR_EN_WROPT rw — Enable Interrupt if avg rssi crosses threshold. HW disables this bit after (first) Avg-RSSI-Threshold Interrupt (in order to avoid sequence of interrupts if average rssi toggles around the thershold)
  [28] ROLE_RX_ANT_DIV_ALPHA_RESET_WROPT rw — Every time antenna is switched, the alpha filter needs to be initialized.
  [27:16] ROLE_RX_ANT_DIV_CURIOSITY_WROPT rw — Curiosity second antenna RSSI: [0-127], where: 0=-110dBm, 127=17dBm Default: -75dBm [0x230] in 8.4s. Note: Curiosity representation: 8.4s
  [15:8] ROLE_RX_ANT_DIV_TIMES_VISITED_WROPT rw — Counts the number of frames received by the HW. Reset every antenna switch
  [7:0] ROLE_RX_CURR_ANT_RSSI_WROPT rw — Current antenna filtered RSSI: [0-127], where: 0=-110dBm, 127=17dBm Default: -75dBm [0x23] Note: RSSI representation: 7.0u
0x398 rx_role_rx_avg_rssi access per field reset 0x23 — ROLE-DB for Interrupt of average-RSSI crossing configurable threshold
  [16] MEM_ROLE_RX_ANT_DIV_EN_ANY_RSSI rw — Enable average calculation for any input level of RSSI
  [11:9] MEM_ROLE_RX_AVG_RSSI_THR_ID rw — ID of which frame type set to send interrupt
  [8] MEM_ROLE_RX_AVG_RSSI_THR_DIR rw — Direction of crossing threshold ('0'-down ; '1'-up) (Default: 0)
  [7:0] MEM_ROLE_RX_AVG_RSSI_THR rw — Input threshold for avg-rssi interrupt: [0-127], where: 0=-110dBm, 127=17dBm Default: -75dBm [0x23] Note: RSSI representation: 7.0u
0x3A4 rx_link_attr access per field — Link Rx attributes
  [31] MEM_RX_PBAA_WROPT rw — Set to 0x1 if the link is under Protected Block Ack Agreement (PBAA)
  [30] MEM_RX_SCB_MODE_WROPT rw — Set scoreboard 8 operation mode: 0x0: Regular scoreboard in single TID mode 0x1: Dynamic fragmentation scoreboard in multi TID mode
  [14] MEM_RX_BSSID_INDEX rw — Select between two basic-rate-set one per BSSID
0x3B4 rx_mng_early_trig_ovrd access per field
  [8] RX_MNG_EARLY_TRIG_CLR_WRCL wo — CLEAR early-trigger-indication sr-ff
  [0] RX_MNG_EARLY_TRIG_SET_WRCL wo — SET early-trigger-indication sr-ff
0x3B8 rx_mng_drop_status reset 0x101 — Report of drop_status from rx_manager
  [7:0] RX_MNG_DROP_STATUS — Report of drop_status from rx_manager (raw status - not including the mask or ovrd: rx_mng_drop_dynamic_mask_wropt / rx_mng_drop_ovrd_wropt): assign drop_status[0] = rx_last_no_data_latch ? 1'b0 : ~frame_delivered_to_sw ; assign drop_status[1] = (rx_fcs_bad & rx_mpdu_done) & ~(abort_sticky | fifo_overflow_sticky); // drop by fcs result only when it is valid and only for join at mpdu_done (fcs=pass for push, not valid yet) assign drop_status[2] = key_id_mismatch | key_ptr_too_low; assign drop_status[3] = adu_frm_done_status[0]; // memory access error (adu fd_range_err_during_frm) assign drop_status[4] = abort_sticky & ~(bet_abort_cng_mode_latch | bet_suspend_decision | rx_last_no_data_latch) ; assign drop_status[5] = adu_frm_done_status[2]; // mpdu_too_long (adu fd_payload_gt_max) assign drop_status[6] = fifo_overflow_sticky; assign drop_status[7] = 1'b0; // place holder for future
0x3BC rx_mng_rsvd_frame access per field reset 0x3F — Reserved frames which are dropped in rx-mng
  [5:0] MEM_CFG_FRAME_TYPE_TO_RSVD rw — Configuration for any frame type (type+subtype) we wish to drop if received. It avoids the RX state machine from continue to valid script, and goes to SCR_TYPE_ERROR state Defualt value is 'FRM_TS_EXT_RSVD_F' (6'b1111_11)
0x3C0 rx_mng_is_aes_valid access per field
  [0] RX_MNG_IS_AES_VALID_WROPT rw — flag set by rx_scripter as indication to rx_manager FSM
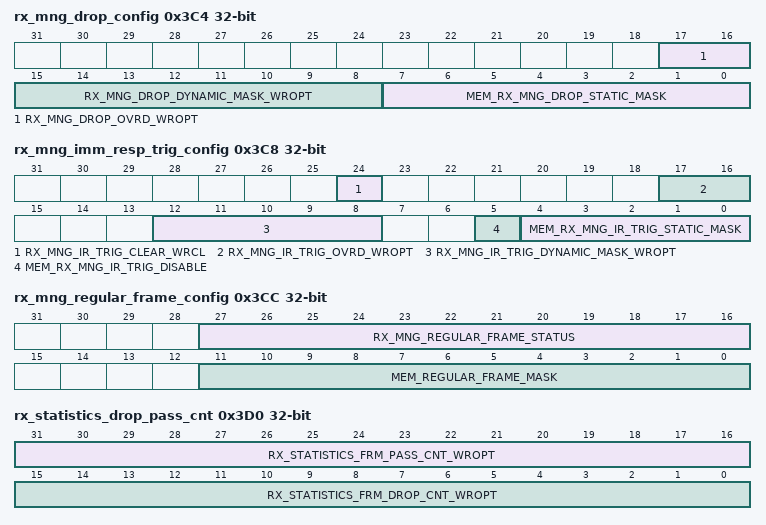
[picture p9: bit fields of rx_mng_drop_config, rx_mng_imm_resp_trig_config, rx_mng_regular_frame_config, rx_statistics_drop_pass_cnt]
0x3C4 rx_mng_drop_config access per field
  [17:16] RX_MNG_DROP_OVRD_WROPT rw — bit[0] = drop override value: 0=pass ; 1=drop bit[1] = drop override select: 0=no override ; 1=override according to bit[0]
  [15:8] RX_MNG_DROP_DYNAMIC_MASK_WROPT rw — dynamic bit-mask for drop decision. see STATIC for bit-mapping wropt - can be loaded by RX_SCR before push/join
  [7:0] MEM_RX_MNG_DROP_STATIC_MASK rw — static mask for drop decision, copied to dynamic mask by rx_manager at every new mpdu start. [0] = wifi filter frame_delivered_to_sw [1] = bad fcs result (but not on aborted packet) [2] = key_id_mismatch or key_ptr_too_low [3] = adu memory access error [4] = abort (but not due to Beacon suspended or early terminated) [5] = adu mpdu_too_long [6] = bb 'fifo_overflow_sticky' [7] = (spare)
0x3C8 rx_mng_imm_resp_trig_config access per field
  [24] RX_MNG_IR_TRIG_CLEAR_WRCL wo — Writing to this bit will clear the immediate response trigger decision that was latched (before the override MUX). Note: a. Any val written to this WRCL bit will kill IR for current ppdu b. Valid for current ppdu only (not a "general IR killer") c. If this bit is cleared, consider clearing 'RX_MNG_TB_TRIG_CLEAR_WRCL' as well
  [17:16] RX_MNG_IR_TRIG_OVRD_WROPT rw — bit[0] = immediate response trigger override value: 0=no trigger ; 1=enable trigger bit[1] = immediate response trigger override select: 0=no override ; 1=override according to bit[0]
  [12:8] RX_MNG_IR_TRIG_DYNAMIC_MASK_WROPT rw — dynamic bit-mask for immediate response trigger. see STATIC for bit-mapping wropt - can be loaded by RX_SCR after new PPDU start
  [5] MEM_RX_MNG_IR_TRIG_DISABLE rw — '1' - disable immediate response trigger. static value, stronger than OVRD_WROPT register that is cleared at everu PPDU start
  [4:0] MEM_RX_MNG_IR_TRIG_STATIC_MASK rw — static mask for immediate response trigger, copied to dynamic mask by rx_manager at every new ppdu start. [0] = at_leased_one_fcs_good (mask=1 will generate IR as if FCS=good) [1] = adu memory access error (mask=1 will generate IR even if memory error - as if 'adu_memory_fail==0') [2] = rx_last_received (mask=1 will set IR before rx_last; DANGEROUS, set with caution) [3] = abort (mask=1 will allow IR after abort, at mask=0 IR will not be triggered at abort) [4] = wifi filter imm_resp_trigger required (mask = 1 will override wifi-filter output to '1' and will reccomend IR)
0x3CC rx_mng_regular_frame_config access per field reset not defined
  [27:16] RX_MNG_REGULAR_FRAME_STATUS ro — [ 0] = no decrypt required [ 1] = good fcs [ 2] = no aes mic fail [ 3] = no adu memory access error [ 4] = not aborted [ 5] = frame type is data [ 6] = ethertype is data (match) [ 7] = not part of amsdu [ 8] = not part of ampdu [ 9] = known link (is_link) [10] = known role (is_role) [11] = frame is not fragmented
  [11:0] MEM_REGULAR_FRAME_MASK rw — mask bits for regular frame indication. see frame_status description
0x3D0 rx_statistics_drop_pass_cnt rw
  [31:16] RX_STATISTICS_FRM_PASS_CNT_WROPT — counter of number of frames passed to SW (rx_complete) clear on write 0 freeze at max value of eather DROP_CNT or PASS_CNT NOTE: need to set mem_rx_statistics_en=1
  [15:0] RX_STATISTICS_FRM_DROP_CNT_WROPT — counter of number of frames dropped (de-alloc) clear on write 0 freeze at max value of eather DROP_CNT or PASS_CNT NOTE: need to set mem_rx_statistics_en=1
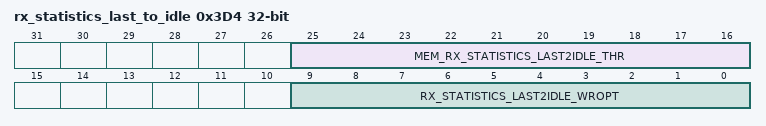
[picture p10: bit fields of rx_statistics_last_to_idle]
0x3D4 rx_statistics_last_to_idle access per field reset not defined
  [25:16] MEM_RX_STATISTICS_LAST2IDLE_THR rw — threshold for generation IRQ if time elapsed from RX_LAST to RX_FRM_STB (manager-go-to-idle) is equal or above this threshold count in clock cycles (20MHz, 50ns) NOTE: need to set mem_rx_statistics_en=1
  [9:0] RX_STATISTICS_LAST2IDLE_WROPT rw — time elapsed from RX_LAST to RX_FRM_STB (manager-go-to-idle) count in clock cycles contain the max-hold value since cleared. clear by write 0 NOTE: need to set mem_rx_statistics_en=1
